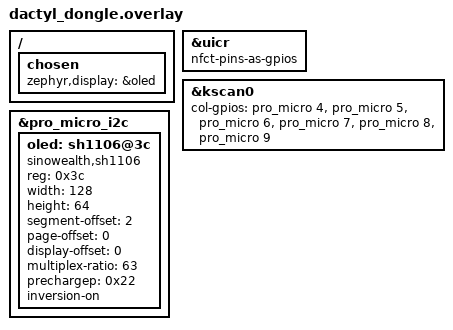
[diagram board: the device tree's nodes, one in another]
/*
 * The dongle is a bare nice_nano acting as the BLE central + USB host + OLED.
 * It has no switches of its own, so it reuses the same kscan/physical-layout
 * as the left half (unused GPIOs, harmless) purely so the shared keymap's
 * bindings line up with the layout position count. The only things that
 * matter functionally here are the BLE central role (set in Kconfig.defconfig)
 * and the OLED wired over I2C.
 */
#include "dactyl.dtsi"

&uicr {
    nfct-pins-as-gpios;
};

&kscan0 {
    col-gpios
        = <&pro_micro 4 GPIO_ACTIVE_HIGH>
        , <&pro_micro 5 GPIO_ACTIVE_HIGH>
        , <&pro_micro 6 GPIO_ACTIVE_HIGH>
        , <&pro_micro 7 GPIO_ACTIVE_HIGH>
        , <&pro_micro 8 GPIO_ACTIVE_HIGH>
        , <&pro_micro 9 GPIO_ACTIVE_HIGH>
        ;
};

/ {
    chosen {
        zephyr,display = &oled;
    };
};

&pro_micro_i2c {
    status = "okay";

    oled: sh1106@3c {
        compatible = "sinowealth,sh1106";
        reg = <0x3c>;
        width = <128>;
        height = <64>;
        segment-offset = <2>;
        page-offset = <0>;
        display-offset = <0>;
        multiplex-ratio = <63>;
        prechargep = <0x22>;
        inversion-on;
    };
};
